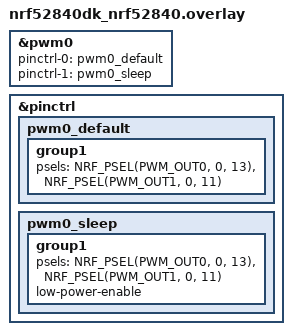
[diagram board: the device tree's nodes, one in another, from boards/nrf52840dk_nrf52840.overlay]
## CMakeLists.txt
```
# SPDX-License-Identifier: Apache-2.0
cmake_minimum_required(VERSION 3.20.0)
find_package(Zephyr REQUIRED HINTS $ENV{ZEPHYR_BASE})
project(SensorNode)
target_include_directories(app PRIVATE ${CMAKE_CURRENT_SOURCE_DIR}/include)
target_sources(app PRIVATE ${CMAKE_CURRENT_SOURCE_DIR}/src/main.c ${CMAKE_CURRENT_SOURCE_DIR}/src/servo.c
${CMAKE_CURRENT_SOURCE_DIR}/src/my_gatt.c ${CMAKE_CURRENT_SOURCE_DIR}/src/ultrasonic.c)
```

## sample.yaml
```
sample:
  name: Task1 - Random Number Display

tests:
  sample.task1.random_display:
    tags:
      - rng
      - uart
      - printk
    filter: dt_enabled_alias_with_parent_compat()
    depends_on: uart
    harness: console
    harness_config:
      type: one_line
      regex: "Random Number: [0-9A-F]{8}"
    integration_platforms:
      - frdm_k64f
      - nrf52840dk_nrf52840
```

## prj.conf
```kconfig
# Core Bluetooth features
CONFIG_BT=y
CONFIG_BT_OBSERVER=y
CONFIG_BT_PERIPHERAL=y      # <-- Required for advertising
CONFIG_BT_BROADCASTER=y     # <-- Also required for bt_le_adv_*
#CONFIG_BT_EXT_ADV=y
CONFIG_BT_MAX_CONN=2

CONFIG_BT_L2CAP_TX_BUF_COUNT=30
CONFIG_BT_BUF_ACL_RX_COUNT=30
CONFIG_BT_BUF_EVT_RX_COUNT=10
CONFIG_BT_BUF_CMD_TX_COUNT=10

CONFIG_THREAD_STACK_INFO=y
CONFIG_STACK_SENTINEL=y
CONFIG_STACK_CANARIES=y

CONFIG_BT_SMP=y
#CONFIG_BT_BONDABLE=y

# Enable persistent CCC descriptor storage for notifications
CONFIG_BT_GATT_CACHING=y
#CONFIG_BT_GATT_CLIENT_CACHING=y  # (optional, more relevant for client)

# Enable Identity tracking
#CONFIG_BT_PRIVACY=y
#CONFIG_BT_ID_MAX=1

# Enable settings subsystem
CONFIG_SETTINGS=y
# Enable Bluetooth settings integration
CONFIG_BT_SETTINGS=y
# Enable system settings load at boot
#CONFIG_SETTINGS_LOAD_ON_BOOT=y

# Thread stack sizes
CONFIG_HEAP_MEM_POOL_SIZE=30000
CONFIG_MAIN_STACK_SIZE=4096
CONFIG_SYSTEM_WORKQUEUE_STACK_SIZE=4096

#Additional bluetooth configs
CONFIG_BT_DEVICE_NAME="Zephyr_GATT_Server"
CONFIG_BT_DEVICE_APPEARANCE=0

#CONFIG_BT_DEBUG_LOG=y  # Optional, for debugging

# Enable logging
CONFIG_STDOUT_CONSOLE=y
CONFIG_LOG=y
CONFIG_LOG_PRINTK=y       # Enables printk() to go to log
CONFIG_LOG_BACKEND_UART=y # Disable UART log backend

CONFIG_GPIO=y

CONFIG_BT_HCI=y
CONFIG_BT_HCI_ACL_FLOW_CONTROL=y
CONFIG_BT_CTLR=n       # If you're using an external controller

#PWM configs
CONFIG_GPIO=y
CONFIG_PWM=y
CONFIG_PWM_NRFX=y

# Enable persistent storage using flash
CONFIG_STREAM_FLASH=y
CONFIG_FLASH=y
CONFIG_FLASH_MAP=y
CONFIG_NVS=y
CONFIG_MPU_ALLOW_FLASH_WRITE=y

# Enable MCUboot
CONFIG_BOOTLOADER_MCUBOOT=y

CONFIG_IMG_MANAGER=y
CONFIG_MCUBOOT_IMG_MANAGER=y
CONFIG_MCUBOOT_UPDATE_FOOTER_SIZE=0x1000

CONFIG_BOOTLOADER_MCUBOOT=y
CONFIG_IMG_MANAGER=y  
```

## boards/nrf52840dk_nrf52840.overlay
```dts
&pwm0 {
    status = "okay";
    pinctrl-0 = <&pwm0_default>;
    pinctrl-1 = <&pwm0_sleep>;
    pinctrl-names = "default", "sleep";
};

&pinctrl {
    pwm0_default: pwm0_default {
        group1 {
            psels = <NRF_PSEL(PWM_OUT0, 0, 13)>,
                    <NRF_PSEL(PWM_OUT1, 0, 11)>;  // Add second PWM channel
                };
    };

    pwm0_sleep: pwm0_sleep {
        group1 {
            psels = <NRF_PSEL(PWM_OUT0, 0, 13)>,
                    <NRF_PSEL(PWM_OUT1, 0, 11)>;  // Same here for sleep mode
                    low-power-enable;
        };
    };
};
```

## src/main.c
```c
/*
 * Copyright (c) 2018 Henrik Brix Andersen <henrik@brixandersen.dk>
 *
 * SPDX-License-Identifier: Apache-2.0
 */
#include <zephyr/bluetooth/bluetooth.h>
#include <zephyr/bluetooth/hci.h>
#include <zephyr/bluetooth/gatt.h>
#include <zephyr/settings/settings.h>
#include <zephyr/sys/printk.h>
#include "my_gatt.h"
#include "servo.h"
#include "ultrasonic.h"
//#include "ultrasonic.h"

int main(void) {
    printk("Program startup\r\n");

    k_mutex_init(&PanAngleAccess);

    // /* Set a fixed static random address: f6:0b:b0:69:12:C6 */
    // bt_addr_le_t static_addr = {
    //     .type = BT_ADDR_LE_RANDOM,
    //     .a.val = { 0xC6, 0x12, 0x69, 0xb0, 0x0b, 0xF6 } // Little-endian
    // };

    // // int id = bt_id_create(&static_addr, NULL);
    // if (id < 0) {
    //     printk("Failed to create static identity (err %d)\n", id);
    // } else {
    //     printk("Created identity ID %d\n", id);
    // }

    int err = bt_enable(bt_ready);
    if (err) {
        printk("Bluetooth enable failed (err %d)\n", err);
        return 0;
    }

    ultrasonic_init();
    servo_start_thread();
    //ultrasonic_thread_init(); //just does not need the extra thread for it, all operations done in servo

    printk("All setup is complete\r\n");
    return 0;
}
```

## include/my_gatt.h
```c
#include <zephyr/kernel.h>
#include <zephyr/arch/cpu.h>
#include <zephyr/sys/util.h>

#ifndef MY_GATT_H
#define MY_GATT_H

#pragma once

/* Custom Service UUID */
#define BT_UUID_CUSTOM_SERVICE_VAL \
	BT_UUID_128_ENCODE(0x12345678, 0x1234, 0x5678, 0x1234, 0x56789abcdef0)

#define BT_UUID_ANGLE_CHAR_VAL \
	BT_UUID_128_ENCODE(0xabcdabcd, 0xabcd, 0xabcd, 0xabcd, 0xabcdabcdef01)

#define BT_UUID_DISTANCE_CHAR_VAL \
	BT_UUID_128_ENCODE(0xdcbaabcd, 0xdcba, 0xdcba, 0xdcba, 0xdcbaabcdef02)

#define BT_UUID_POWER_STATE_VAL \
	BT_UUID_128_ENCODE(0x87654321, 0x4321, 0x8765, 0x4321, 0xabcdef123456)

#define BT_UUID_TRACKING_STATE_VAL \
	BT_UUID_128_ENCODE(0xabcdef01, 0x2345, 0x6789, 0xabcd, 0xef0123456789)

#define DEVICE_NAME CONFIG_BT_DEVICE_NAME
#define DEVICE_NAME_LEN (sizeof(DEVICE_NAME) - 1)
#define MAX_BT_CONNECTIONS CONFIG_BT_MAX_CONN

extern bool angle_notify_enabled;
extern bool distance_notify_enabled;

void bt_ready(int err);
void notify_distance(uint16_t dist);
void notify_angle(int16_t degrees);

#endif // SERVO_H
```

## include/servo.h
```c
//inclide libaries here
#include <zephyr/device.h>
#include <zephyr/drivers/pwm.h>
#include <zephyr/kernel.h>
#include <zephyr/sys/printk.h>

#ifndef SERVO_H
#define SERVO_H

#pragma once

typedef enum {
    MODE_SWEEP,
    MODE_TRACK
} servo_mode_t;

typedef struct servoState{
    servo_mode_t mode;
    int angle;
    int8_t step;
    int64_t timestamp;
    bool angle_pending;
} servo_info_t;

void servo_init(void);
void servo_start_thread(void);
void servo_set_target_angle_pan(int angle);

extern struct k_mutex PanAngleAccess;
extern volatile servo_info_t servo_info;

extern volatile uint8_t turret_state;

#endif // SERVO_H
```

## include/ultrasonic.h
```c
#ifndef ULTRASONIC_H
#define ULTRASONIC_H

#include <zephyr/drivers/gpio.h>
#include <zephyr/kernel.h>

// Shared distance value (in cm)
extern volatile uint16_t ultrasonic_distance_cm;
extern const struct device *gpio_dev;

// Function to start the ultrasonic thread
void ultrasonic_init(void);
uint16_t measure_distance_cm(const struct device *gpio);

#endif // ULTRASONIC_H
```

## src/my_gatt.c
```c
#include <zephyr/bluetooth/bluetooth.h>
#include <zephyr/bluetooth/hci.h>
#include <zephyr/bluetooth/gatt.h>
#include <zephyr/settings/settings.h>
#include <zephyr/sys/printk.h>
#include <string.h>
#include <stdbool.h>
#include "my_gatt.h"
#include "servo.h"

// Subscription counts per characteristic
static int8_t angle_sub_count = 0;
static int8_t distance_sub_count = 0;
static int8_t power_sub_count = 0;
static int8_t track_sub_count = 0;
static int8_t connection_count = 0;

static struct bt_uuid_128 custom_service_uuid = BT_UUID_INIT_128(BT_UUID_CUSTOM_SERVICE_VAL);
static struct bt_uuid_128 angle_uuid = BT_UUID_INIT_128(BT_UUID_ANGLE_CHAR_VAL);
static struct bt_uuid_128 distance_uuid = BT_UUID_INIT_128(BT_UUID_DISTANCE_CHAR_VAL);
static struct bt_uuid_128 tracking_state_uuid = BT_UUID_INIT_128(BT_UUID_TRACKING_STATE_VAL); 
static struct bt_uuid_128 power_state_uuid = BT_UUID_INIT_128(BT_UUID_POWER_STATE_VAL);//can use from jetson to indicate when to actually read distance

/* Application State */
static int16_t angle = 0;
static int16_t distance = 0;
static uint8_t power_state = 1;
static uint8_t tracking_state = 1;

/* Advertisement data */
static const struct bt_data ad[] = {
    BT_DATA_BYTES(BT_DATA_FLAGS, (BT_LE_AD_GENERAL | BT_LE_AD_NO_BREDR)),
    BT_DATA_BYTES(BT_DATA_UUID128_ALL, BT_UUID_CUSTOM_SERVICE_VAL),
};

static const struct bt_data sd[] = {
    BT_DATA(BT_DATA_NAME_COMPLETE, DEVICE_NAME, DEVICE_NAME_LEN),
};


static struct k_work_delayable adv_restart_work;

static void adv_restart(struct k_work *work)
{
    int err = bt_le_adv_stop();
    if (err && err != -EALREADY) {
        printk("Failed to stop advertising: %d\n", err);
        return;
    }

    err = bt_le_adv_start(BT_LE_ADV_CONN_FAST_1, ad, ARRAY_SIZE(ad), sd, ARRAY_SIZE(sd));
    if (err) {
        printk("Failed to restart advertising: %d\n", err);
    } else {
        printk("Restarted advertising (via work queue)\n");
    }
}

/* CCC callbacks - track subscription count */
static void angle_ccc_cfg_changed(const struct bt_gatt_attr *attr, uint16_t value)
{
    if (value == BT_GATT_CCC_NOTIFY) {
        angle_sub_count++;
    } else {
        angle_sub_count--;
        if (angle_sub_count < 0) angle_sub_count = 0;
    }
    printk("Angle notifications %s, subscribers: %d\n",
           value == BT_GATT_CCC_NOTIFY ? "enabled" : "disabled", angle_sub_count);
}

static void distance_ccc_cfg_changed(const struct bt_gatt_attr *attr, uint16_t value)
{
    if (value == BT_GATT_CCC_NOTIFY) {
        distance_sub_count++;
    } else {
        distance_sub_count--;
        if (distance_sub_count < 0) distance_sub_count = 0;
    }
    printk("Distance notifications %s, subscribers: %d\n",
           value == BT_GATT_CCC_NOTIFY ? "enabled" : "disabled", distance_sub_count);
}

static void power_ccc_cfg_changed(const struct bt_gatt_attr *attr, uint16_t value)
{
    if (value == BT_GATT_CCC_NOTIFY) {
        power_sub_count++;
    } else {
        power_sub_count--;
        if (power_sub_count < 0) power_sub_count = 0;
    }
    printk("Power notifications %s, subscribers: %d\n",
           value == BT_GATT_CCC_NOTIFY ? "enabled" : "disabled", power_sub_count);
}

static void track_ccc_cfg_changed(const struct bt_gatt_attr *attr, uint16_t value)
{
    if (value == BT_GATT_CCC_NOTIFY) {
        track_sub_count++;
    } else {
        track_sub_count--;
        if (track_sub_count < 0) track_sub_count = 0;
    }
    printk("Tracking notifications %s, subscribers: %d\n",
           value == BT_GATT_CCC_NOTIFY ? "enabled" : "disabled", track_sub_count);
}

// Work item and associated data
static struct k_work angle_work;

// Worker function
static void angle_work_handler(struct k_work *work) {
    servo_info_t local;
    int err;

    // Safely update shared data
    //k_mutex_lock(&PanAngleAccess, K_FOREVER);
    servo_info.angle = angle;
    servo_info.angle_pending = true;
    local = servo_info;
    //k_mutex_unlock(&PanAngleAccess);

    printk("Angle updated by client (deferred): %d\n", servo_info.angle);
}

// Init function (call once during init or main)
void angle_work_init(void) {
    k_work_init(&angle_work, angle_work_handler);
}

static ssize_t write_angle(struct bt_conn *conn, const struct bt_gatt_attr *attr,
                           const void *buf, uint16_t len, uint16_t offset, uint8_t flags) {

    if (len != sizeof(int16_t)) {
        return BT_GATT_ERR(BT_ATT_ERR_INVALID_ATTRIBUTE_LEN);
    }

    memcpy(&angle, buf, sizeof(angle));

    // Offload work to avoid blocking the GATT stack
    k_work_submit(&angle_work);

    return sizeof(angle);
}

// static ssize_t write_angle(struct bt_conn *conn, const struct bt_gatt_attr *attr,
// 		       const void *buf, uint16_t len, uint16_t offset, uint8_t flags) {

// 	if (len != sizeof(int16_t)) return BT_GATT_ERR(BT_ATT_ERR_INVALID_ATTRIBUTE_LEN);

// 	memcpy(&angle, buf, sizeof(angle));
//     k_mutex_lock(&PanAngleAccess,K_FOREVER);
//     servo_info.angle = angle;
//     servo_info.angle_pending = true;
//     k_mutex_unlock(&PanAngleAccess);
// 	printk("Angle updated by client: %d\n", angle);
//     int err;

    
//     // err = k_msgq_put(&angleData,&local,K_NO_WAIT);

//     // //check if full and remove latest element and resend if so
//     // if(err == -ENOMSG || err == -ENOMEM) {
//     //     servo_info_t discard;
//     //     k_msgq_get(&angleData,&discard,K_NO_WAIT);
//     //     k_msgq_put(&angleData,&local,K_NO_WAIT);
//     // }
//     //can notify like this in this configuration
//     // if (angle_sub_count > 0) {
//     //     bt_gatt_notify(NULL, attr, &angle, sizeof(angle));
//     // }

// 	return sizeof(angle);
// }

//variable may not be used, but implemented in case it is needed
static ssize_t write_power_state(struct bt_conn *conn, const struct bt_gatt_attr *attr,
                                 const void *buf, uint16_t len, uint16_t offset,uint8_t flags)
{
    if (len != sizeof(uint8_t)) {
        return BT_GATT_ERR(BT_ATT_ERR_INVALID_ATTRIBUTE_LEN);
    }
    uint8_t new_val = *((uint8_t *)buf);

    if (new_val != power_state) {
        power_state = new_val;

        turret_state = power_state;

        printk("Power state updated to: %d\n", power_state);

        //it should notifiy given jetson should be subscribed to this
        // if (power_sub_count > 0) {
        //     bt_gatt_notify(NULL, attr, &power_state, sizeof(power_state));
        // }
    }

    return len;
}

static ssize_t write_tracking_state(struct bt_conn *conn, const struct bt_gatt_attr *attr,
                                    const void *buf, uint16_t len, uint16_t offset, uint8_t flags)
{
    if (len != sizeof(uint8_t)) {
        return BT_GATT_ERR(BT_ATT_ERR_INVALID_ATTRIBUTE_LEN);
    }

    uint8_t new_val = *((uint8_t *)buf);

    if (new_val != tracking_state) {
        tracking_state = new_val;

        printk("Tracking state updated to: %d\n", tracking_state);

        //same here, tracking state is internal
        // if (track_sub_count > 0) {
        //     bt_gatt_notify(NULL, attr, &tracking_state, sizeof(tracking_state));
        // }
    }

    return len;
}

/* GATT service definition */
BT_GATT_SERVICE_DEFINE(custom_svc,
	BT_GATT_PRIMARY_SERVICE(&custom_service_uuid),

    /* Read-only characteristic with notify: Distance */
	BT_GATT_CHARACTERISTIC(&distance_uuid.uuid,
		BT_GATT_CHRC_READ | BT_GATT_CHRC_NOTIFY,
		BT_GATT_PERM_READ, NULL, NULL, &distance),
	BT_GATT_CCC(distance_ccc_cfg_changed, BT_GATT_PERM_READ | BT_GATT_PERM_WRITE),

	/* Read-write characteristic with notify: Angle */
	BT_GATT_CHARACTERISTIC(&angle_uuid.uuid,
		BT_GATT_CHRC_READ | BT_GATT_CHRC_WRITE | BT_GATT_CHRC_NOTIFY,
		BT_GATT_PERM_READ | BT_GATT_PERM_WRITE, NULL, write_angle, &angle),
	BT_GATT_CCC(angle_ccc_cfg_changed, BT_GATT_PERM_READ | BT_GATT_PERM_WRITE),

    /* Power state characteristic */
    BT_GATT_CHARACTERISTIC(&power_state_uuid.uuid,
        BT_GATT_CHRC_READ | BT_GATT_CHRC_WRITE | BT_GATT_CHRC_NOTIFY,
        BT_GATT_PERM_READ | BT_GATT_PERM_WRITE,
        NULL, write_power_state, &power_state),
    BT_GATT_CCC(power_ccc_cfg_changed, BT_GATT_PERM_READ | BT_GATT_PERM_WRITE),

    /* Tracking state characteristic */
    BT_GATT_CHARACTERISTIC(&tracking_state_uuid.uuid,
        BT_GATT_CHRC_READ | BT_GATT_CHRC_WRITE | BT_GATT_CHRC_NOTIFY,
        BT_GATT_PERM_READ | BT_GATT_PERM_WRITE,
        NULL, write_tracking_state, &tracking_state),
    BT_GATT_CCC(track_ccc_cfg_changed, BT_GATT_PERM_READ | BT_GATT_PERM_WRITE),
);

/* Notify helpers */
void notify_distance(uint16_t dist) {
    if(dist == 0 || tracking_state == 0) { //return if no valid reading or not tracking currently
        return;
    }
    distance = dist;

    if (distance_sub_count > 0) {
        bt_gatt_notify(NULL, &custom_svc.attrs[2], &distance, sizeof(distance));
    }
}

void notify_angle(int16_t degrees) {
    //angle = degrees;

    if (angle_sub_count > 0) {
        bt_gatt_notify(NULL, &custom_svc.attrs[5], &degrees, sizeof(degrees));
    }
}

static void connected(struct bt_conn *conn, uint8_t err)
{
    if (err) {
        printk("Connection failed (err %u)\n", err);
    } else {
        connection_count++;
        printk("Connected to %u/%u clients\n",connection_count, MAX_BT_CONNECTIONS);
        if(connection_count < MAX_BT_CONNECTIONS) {
            printk("connection count: %d\r\n",connection_count);
            k_work_schedule(&adv_restart_work, K_NO_WAIT);
        }
    }
}

static void disconnected(struct bt_conn *conn, uint8_t reason)
{   
    connection_count--;
    printk("Disconnected %u/%u, (reason %u)\n",connection_count,MAX_BT_CONNECTIONS,reason);

    //restart advertising if new slot was made available, otherwise do not start(connection already handles that case)
    k_work_schedule(&adv_restart_work, K_NO_WAIT);
}

static void setup_advertising(void) {
    int err = bt_le_adv_start(BT_LE_ADV_CONN_FAST_1, ad, ARRAY_SIZE(ad), sd, ARRAY_SIZE(sd));
    if (err) {
        printk("Advertising failed to start (err %d)\n", err);
    } else {
        printk("Advertising started\n");
    }
}

static struct bt_conn_cb conn_callbacks = {
    .connected = connected,
    .disconnected = disconnected,
};

void bt_ready(int err)
{
    if (err) {
        printk("Bluetooth init failed (err %d)\n", err);
        return;
    }

    printk("Bluetooth initialized\n");

    bt_conn_cb_register(&conn_callbacks);

    if (IS_ENABLED(CONFIG_SETTINGS)) {
		settings_load();
	}


    angle_work_init();
    k_work_init_delayable(&adv_restart_work, adv_restart);
    setup_advertising();
}
```

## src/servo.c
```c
#include "servo.h"
#include "ultrasonic.h"
#include "my_gatt.h"

#define PWM_PERIOD_USEC 20000 // 20ms = 50Hz
#define SERVO_MIN_US 500
#define SERVO_MAX_US 2500
#define SERVO_DEFAULT_ANGLE 90
#define TILT_BOOT_ANGLE 45 // Set once at boot

#define PAN_CHANNEL 0  // P0.13 (PWM_OUT0)
#define TILT_CHANNEL 1 // P0.11 (PWM_OUT1)

#define TIMEOUT_MS 2000
#define SWEEP_ANGLE_UPDATE_RESOLUTION 5

//cannot track under current setup
#define HEURISTIC_DISTANCE_THRESHOLD 100 //(cm)
#define HEURISTIC_MAX_DISTANCE_DIFFERENCE 20 //(cm)

static const struct device *pwm_dev;
static volatile int target_angle_pan = SERVO_DEFAULT_ANGLE;

struct k_mutex PanAngleAccess;
volatile servo_info_t servo_info;

// struct k_mutex PowerStateAccess;
volatile uint8_t turret_state = 1;

/* === Angle to pulse width === */
static uint32_t angle_to_pulse(int degrees) {
    if (degrees < 0)
        degrees = 0;
    if (degrees > 180)
        degrees = 180;
    return SERVO_MIN_US + ((degrees * (SERVO_MAX_US - SERVO_MIN_US)) / 180);
}

/* === Set pan angle externally (from BLE) === */
void servo_set_target_angle_pan(int angle) {
    if (angle < 0)
        angle = 0;
    if (angle > 180)
        angle = 180;
    target_angle_pan = angle;
    printk("[SERVO] Pan target set to: %d\n", angle);
}

/* === Move a PWM channel to angle === */
static void move_servo_channel(int channel, int angle) {
    uint32_t pulse = angle_to_pulse(angle);
    int err = pwm_set(pwm_dev, channel, PWM_USEC(PWM_PERIOD_USEC),
                      PWM_USEC(pulse), PWM_POLARITY_NORMAL);
    if (err) {
        printk("[SERVO] PWM CH%d set failed: %d\n", channel, err);
    } else {
        //printk("[SERVO] CH%d → angle=%d → pulse=%dus\n", channel, angle, pulse);
    }
}

static void start_sweep(servo_info_t* info) {
    int difference = SERVO_DEFAULT_ANGLE - info->angle;
    if(difference < 0) {
        info->step = -1;
    } else {
        info->step = 1;
    }
}

static void update_sweep(servo_info_t* info) {

    if(info->angle == 180 || info->angle == 0) {
        info->step = -1 * info->step;
    }

    info->angle += info->step;
    move_servo_channel(PAN_CHANNEL, info->angle);

}

/* === Init: set tilt once and center pan === */
void servo_init(void) {
    pwm_dev = DEVICE_DT_GET(DT_NODELABEL(pwm0));
    if (!device_is_ready(pwm_dev)) {
        printk("[SERVO] PWM0 not ready!\n");
        return;
    }

    move_servo_channel(PAN_CHANNEL, SERVO_DEFAULT_ANGLE);
    move_servo_channel(TILT_CHANNEL, TILT_BOOT_ANGLE); // Set once

    printk("[SERVO] Initialized (Pan: CH0 → P0.13, Tilt: CH1 → P0.11)\n");
}

/* === Pan update loop === */
void servo_thread(void) {
    int last_pan = -1;
    int64_t time_now = 0;
    int16_t sonic_distance = 0;
    int64_t prev_angle = 90;
    uint8_t count = 0;
    int angleStatus = 1;
    int angle = 90;
    int step = 2;

    //set inital state:
    servo_info.angle = SERVO_DEFAULT_ANGLE;
    servo_info.angle_pending = false;
    servo_info.mode = MODE_SWEEP;
    start_sweep(&servo_info);

    //should it notify with inital value?

    printk("Servo thread started\r\n");
    while (1) {

        //do nothing if the turret is turned off
        if(turret_state == 0) {
            k_sleep(K_MSEC(50));
            continue;
        }

        //k_mutex_lock(&PanAngleAccess,K_FOREVER);
        switch(servo_info.mode) {
            case MODE_TRACK:
                if(servo_info.angle_pending) {
                    //reset pending
                    servo_info.angle_pending = false;

                    //update timestamp
                    //servo_info.timestamp = k_uptime_get();
                    time_now = 0;

                    if(servo_info.angle < 0) {
                        //move left
                        angle += servo_info.angle;

                        if (angle < 0) {
                            angle = 0;
                        } else if (angle > 180) {
                            angle = 180;
                        }
                        
                        move_servo_channel(PAN_CHANNEL, angle);
                        notify_angle(angle);
                    } else if(servo_info.angle > 0) {
                        //move right
                        angle += servo_info.angle;

                        if (angle < 0) {
                            angle = 0;
                        } else if (angle > 180) {
                            angle = 180;
                        }

                        move_servo_channel(PAN_CHANNEL, angle);
                        notify_angle(angle);
                    } else {

                        sonic_distance = measure_distance_cm(gpio_dev);
                        printk("sonic_distance: %d\r\n",sonic_distance);
                        notify_distance(sonic_distance); 
                        notify_angle(angle);
                    }
                } else {
                    // time_now = k_uptime_get();
                    // //check timeout
                    // if(time_now - local.timestamp >= TIMEOUT_MS) {
                    //     local.mode = MODE_SWEEP;
                    //     start_sweep(&local);
                    // }
                    time_now++;
                    printk("time now: %d\r\n",time_now);
                    if(time_now >= 60) {
                        time_now = 0;
                        servo_info.mode = MODE_SWEEP;
                        start_sweep(&servo_info);
                    }
                }
                k_sleep(K_MSEC(50));
                //k_mutex_unlock(&PanAngleAccess); 
                break;

            case(MODE_SWEEP):
                if(servo_info.angle_pending) {
                    servo_info.mode = MODE_TRACK;
                    angle = prev_angle;
                    printk("switching\r\n");
                    continue;
                }

                update_sweep(&servo_info);
                count++;
                
                //this is only for pretty sweep visualization, so can be removed if not needed
                if(count >= SWEEP_ANGLE_UPDATE_RESOLUTION) {
                    count = 0;
                    prev_angle = servo_info.angle;
                    notify_angle(servo_info.angle);
                }

                //k_mutex_unlock(&PanAngleAccess); 
                k_sleep(K_MSEC(100));
                break;

        }   
    //     //state machine for the servo (mealy given angle pending as input)
    //     switch(local.mode) {
    //         case(MODE_SWEEP):
    //             if(local.angle_pending) {
    //                 local.mode = MODE_TRACK;
    //                 continue;
    //             }

    //             update_sweep(&local);
    //             count++;
                
    //             //this is only for pretty sweep visualization, so can be removed if not needed
    //             if(count >= SWEEP_ANGLE_UPDATE_RESOLUTION) {
    //                 count = 0;
    //                 notify_angle(local.angle);
    //             }

    //             k_sleep(K_MSEC(100));
    //             break;
    //         case(MODE_TRACK):
    //             if(local.angle_pending) {

    //                 //reset pending
    //                 local.angle_pending = false;

    //                 //reset timer
    //                 local.timestamp = k_uptime_get();

    //                 // set angle to new one
    //                 if (last_pan != local.angle) {
    //                     last_pan = local.angle;

    //                     //move servo
    //                     move_servo_channel(PAN_CHANNEL, last_pan);
    //                     printk("[SERVO] Pan target set to: %d\n", local.angle);

    //                     //get distance at angle
    //                     sonic_distance = measure_distance_cm(gpio_dev);

    //                     //send both updates to all subcribed boards
    //                     notify_angle(last_pan);
    //                     notify_distance(sonic_distance); //need to move this out for close distace heuristics
    //                     last_distance = sonic_distance;

    //                     k_sleep(K_MSEC(10));
    //                 }
    //             } else {
    //                 time_now = k_uptime_get();
    //                 //check timeout
    //                 if(!heuristics_on && (time_now - local.timestamp >= TIMEOUT_MS)) {
    //                     local.mode = MODE_SWEEP;
    //                     start_sweep(&local);
    //                 }
                    
    //                 //get distance for heuristics
    //                 sonic_distance = measure_distance_cm(gpio_dev);

    //                 //get distance difference
    //                 distance_difference = sonic_distance - last_distance;
    //                 if(distance_difference < 0) {
    //                     distance_difference = -distance_difference;
    //                 }

    //                 //apply heuristics
    //                 if(sonic_distance < HEURISTIC_DISTANCE_THRESHOLD && 
    //                         distance_difference <   HEURISTIC_MAX_DISTANCE_DIFFERENCE) {
    //                     heuristics_on = true;

    //                     //send though off position of target
    //                     notify_angle(last_pan);
    //                     notify_distance(sonic_distance); 
    //                 } else {
    //                     heuristics_on = false;
    //                 }

    //                 k_sleep(K_MSEC(100));
    //             }
    //             break;
    //     }

    }
}

/* === Thread management === */
#define SERVO_STACK_SIZE 1024
#define SERVO_THREAD_PRIORITY 10

K_THREAD_STACK_DEFINE(servo_stack_area, SERVO_STACK_SIZE);
static struct k_thread servo_thread_data;

void servo_start_thread(void) {
    servo_init();

    k_thread_create(&servo_thread_data, servo_stack_area,
                    K_THREAD_STACK_SIZEOF(servo_stack_area),
                    (k_thread_entry_t)servo_thread, NULL, NULL, NULL,
                    SERVO_THREAD_PRIORITY, 0, K_NO_WAIT);

    printk("[SERVO] Servo thread started\n");
}
```

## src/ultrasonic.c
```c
#include "ultrasonic.h"
#include <zephyr/device.h>
#include <zephyr/drivers/gpio.h>
#include <zephyr/sys/printk.h>

#define TRIG_PIN 3 // P0.03
#define ECHO_PIN 4 // P0.04

#define STACK_SIZE 1024
#define PRIORITY 1

K_THREAD_STACK_DEFINE(ultrasonic_stack, STACK_SIZE);
static struct k_thread ultrasonic_thread_data;

const struct device *gpio_dev;
//volatile uint16_t ultrasonic_distance_cm = 0;

void ultrasonic_init(void) {
    gpio_dev = DEVICE_DT_GET(DT_NODELABEL(gpio0));
    if (!device_is_ready(gpio_dev)) {
        printk("GPIO0 not ready\n");
        return;
    }

    gpio_pin_configure(gpio_dev, TRIG_PIN, GPIO_OUTPUT_INACTIVE);
    gpio_pin_configure(gpio_dev, ECHO_PIN, GPIO_INPUT);
    printk("Ultrasonic GPIOs configured\n");
}

uint16_t measure_distance_cm(const struct device *gpio) {
    uint32_t timeout_us = 30000;
    uint32_t start, end, duration_us;

    gpio_pin_set(gpio, TRIG_PIN, 1);
    k_busy_wait(10);
    gpio_pin_set(gpio, TRIG_PIN, 0);

    uint32_t wait_start = k_cycle_get_32();
    while (gpio_pin_get(gpio, ECHO_PIN) == 0) {
        if (k_cyc_to_us_floor32(k_cycle_get_32() - wait_start) > timeout_us) {
            return 0;
        }
    }

    start = k_cycle_get_32();
    while (gpio_pin_get(gpio, ECHO_PIN) == 1) {
        if (k_cyc_to_us_floor32(k_cycle_get_32() - start) > timeout_us) {
            return 0;
        }
    }

    end = k_cycle_get_32();
    duration_us = k_cyc_to_us_floor32(end - start);

    return (uint16_t)((duration_us * 343) / 20000); // (us × speed) / 2
}

//combine this thread with servo thread 
static void ultrasonic_thread_fn(void *a, void *b, void *c) {

    ultrasonic_init();

    while (1) {
        //ultrasonic_distance_cm = measure_distance_cm(gpio_dev);
        //notify_distance(ultrasonic_distance_cm); //should only track if the tracking is enabled, otherwise just don't
        k_sleep(K_MSEC(500));
    }
}

void ultrasonic_thread_init(void) {
    k_thread_create(&ultrasonic_thread_data, ultrasonic_stack,
                    K_THREAD_STACK_SIZEOF(ultrasonic_stack),
                    ultrasonic_thread_fn, NULL, NULL, NULL, PRIORITY, 0,
                    K_NO_WAIT);
}
```
